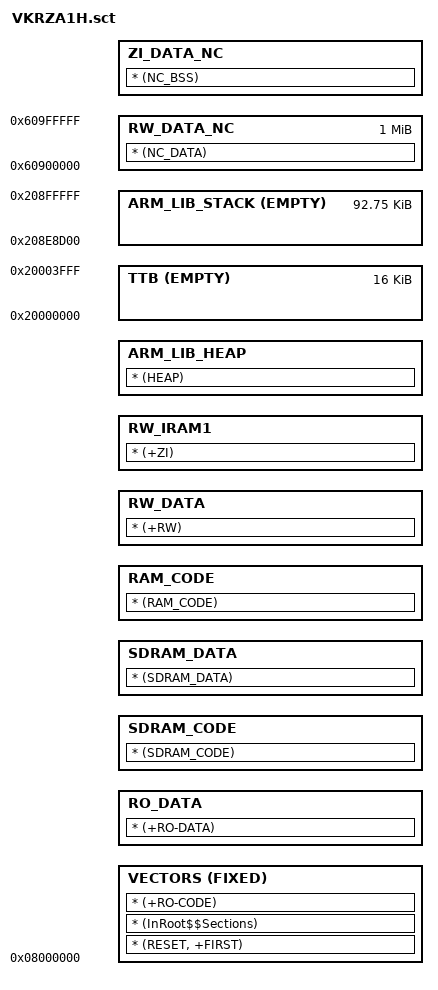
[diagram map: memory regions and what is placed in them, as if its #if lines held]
#! armclang -E --target=arm-arm-none-eabi -x c -mcpu=cortex-a9
;**************************************************
; Copyright (c) 2017 ARM Ltd.  All rights reserved.
;**************************************************

; Scatter-file for RTX Example on Versatile Express

; This scatter-file places application code, data, stack and heap at suitable addresses in the memory map.

#ifdef RUN_FROM_SDRAM
 #define __ROM_BASE       0x08000000
 #define __ROM_SIZE       0x02000000
 #define __DATA_BASE	  0x20020000 ALIGN 0x100000
#elif defined (RUN_FROM_SRAM)
 #define __ROM_BASE       0x200A0000
 #define __ROM_SIZE       0x00960000
 #define __DATA_BASE	  +0 ALIGN 0x100000 NOCOMPRESS
#else
 #define __ROM_BASE       0x18020000
 #define __ROM_SIZE       0x1FE0000
 #define __DATA_BASE	  0x20020000
#endif

#define __RAM_BASE       0x20000000
#define __RAM_SIZE       0x00A00000
#define __NC_RAM_SIZE    0x00100000
#define __NM_RAM_SIZE    (__RAM_SIZE - __NC_RAM_SIZE)
#define __DATA_NC_BASE   (__RAM_BASE + __NM_RAM_SIZE + 0x40000000)

#define __UND_STACK_SIZE 0x00000100
#define __SVC_STACK_SIZE 0x00008000
#define __ABT_STACK_SIZE 0x00000100
#define __FIQ_STACK_SIZE 0x00000100
#define __IRQ_STACK_SIZE 0x0000F000
#define __STACK_SIZE     (__UND_STACK_SIZE + __SVC_STACK_SIZE + __ABT_STACK_SIZE + __FIQ_STACK_SIZE + __IRQ_STACK_SIZE)

#define __TTB_BASE       0x20000000
#define __TTB_SIZE       0x00004000

#if !defined(MBED_APP_START)
  #define MBED_APP_START __ROM_BASE
#endif

#if !defined(MBED_APP_SIZE)
  #define MBED_APP_SIZE  __ROM_SIZE
#endif

LOAD_TTB    __TTB_BASE __TTB_SIZE ; Page 0 of On-Chip Data Retention RAM
{
    TTB     +0 EMPTY 0x4000            
    { }                         ; Level-1 Translation Table for MMU
}

LR_IROM1 MBED_APP_START MBED_APP_SIZE       ; load region size_region
{
  VECTORS MBED_APP_START FIXED
  {
    * (RESET, +FIRST)           ; Vector table and other startup code
    * (InRoot$$Sections)        ; All (library) code that must be in a root region
    * (+RO-CODE)                ; Application RO code (.text)
  }

  RO_DATA       +0
  { * (+RO-DATA) }              ; Application RO data (.constdata)

#if (MBED_APP_START < 0xA000000)
  SDRAM_CODE +0 ALIGN 0x100000
  { * (SDRAM_CODE) }            ; External RAM region (SDRAM)

  SDRAM_DATA +0 ALIGN 0x100000
  { * (SDRAM_DATA) }
#endif

  RAM_CODE      __DATA_BASE
  { * (RAM_CODE) }              ; Internal RAM region (SRAM)

  RW_DATA       +0 ALIGN 0x8
  { * (+RW) }                   ; Application RW data (.data)

  RW_IRAM1      +0 ALIGN 0x10
  { * (+ZI) }                   ; Application ZI data (.bss)

  ARM_LIB_HEAP  +0 ALIGN 0x8
  { * (HEAP) }                  ; Application heap area (HEAP)

  ARM_LIB_STACK (__RAM_BASE + __NM_RAM_SIZE) EMPTY -__STACK_SIZE      ; Stack region growing down
  { }

  ;;;;;;;;;;;;;;;;;;;;;;;;;;;;;;;;;;;;;;;;;;;;;;;;;;;;;;;;;;;;
  ; RAM-NC : Internal non-cached RAM region
  ;;;;;;;;;;;;;;;;;;;;;;;;;;;;;;;;;;;;;;;;;;;;;;;;;;;;;;;;;;;;

  RW_DATA_NC __DATA_NC_BASE __NC_RAM_SIZE
    { * (NC_DATA) }             ; Application RW data Non cached area

    ZI_DATA_NC +0
    { * (NC_BSS) }              ; Application ZI data Non cached area

#if (MBED_APP_START > 0xA000000)
  ;;;;;;;;;;;;;;;;;;;;;;;;;;;;;;;;;;;;;;;;;;;;;;;;;;;;;;;;;;;;
  ; External RAM region (SDRAM)
  ;;;;;;;;;;;;;;;;;;;;;;;;;;;;;;;;;;;;;;;;;;;;;;;;;;;;;;;;;;;;

  SDRAM_CODE 0x08000000 0x2000000
  { * (SDRAM_CODE) }

  SDRAM_DATA +0 ALIGN 0x100000
  { * (SDRAM_DATA) }
#endif
}

